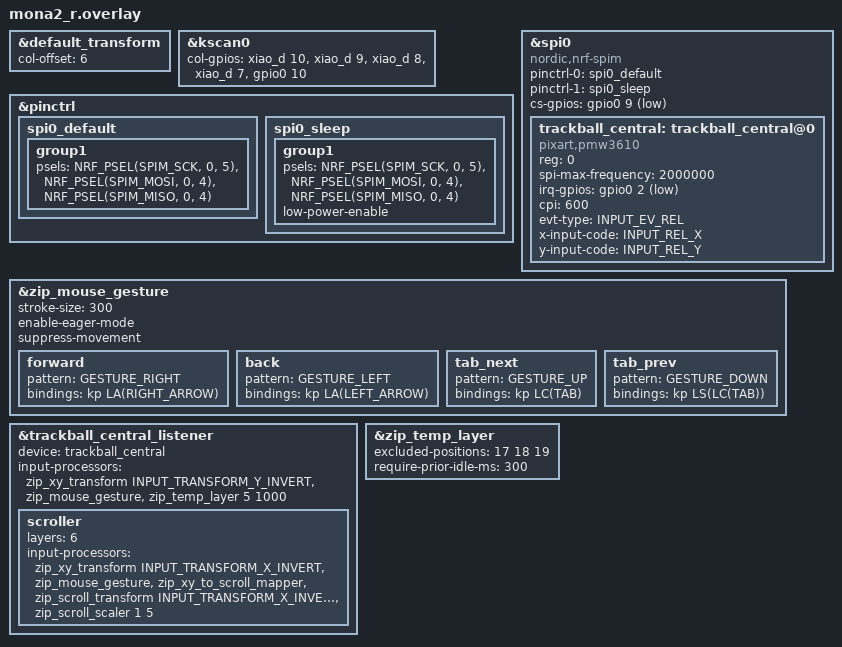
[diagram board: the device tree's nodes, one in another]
#include "mona2.dtsi"
#include <input/processors.dtsi>
#include <zephyr/dt-bindings/input/input-event-codes.h>
#include <dt-bindings/zmk/pointing.h>
#include <dt-bindings/zmk/keys.h>
#include <mouse-gesture.dtsi>


&default_transform {
    col-offset = <6>;
};

&kscan0 {
        col-gpios
            = <&xiao_d 10 GPIO_ACTIVE_HIGH>
            , <&xiao_d 9 GPIO_ACTIVE_HIGH> 
            , <&xiao_d 8 GPIO_ACTIVE_HIGH> 
            , <&xiao_d 7 GPIO_ACTIVE_HIGH> 
            , <&gpio0 10 GPIO_ACTIVE_HIGH>
            ;
};


&pinctrl {
    spi0_default: spi0_default {    //通常時(SPI通信中)のピン構成
        group1 {
            psels = <NRF_PSEL(SPIM_SCK, 0, 5)>, //P0.05を指定(SCLK)
                <NRF_PSEL(SPIM_MOSI, 0, 4)>,    //P0.04を指定(SDIOだからMOSI,MISO両方の役割を担う)
                <NRF_PSEL(SPIM_MISO, 0, 4)>;
        };
    };

    spi0_sleep: spi0_sleep {    //スリープ時のピン構成(省電力)
        group1 {
            psels = <NRF_PSEL(SPIM_SCK, 0, 5)>,
                <NRF_PSEL(SPIM_MOSI, 0, 4)>,
                <NRF_PSEL(SPIM_MISO, 0, 4)>;
            low-power-enable;
        };
    };
};


&spi0 {
    status = "okay";
    compatible = "nordic,nrf-spim"; //マイコンがnRFシリーズ
    pinctrl-0 = <&spi0_default>;
    pinctrl-1 = <&spi0_sleep>;
    pinctrl-names = "default", "sleep";
    cs-gpios = <&gpio0 9 GPIO_ACTIVE_LOW>;  //P0.09を指定(CS)

    trackball_central: trackball_central@0 {
        status = "okay";
        compatible = "pixart,pmw3610";  //トラボセンサ用のドライバとバインド
        reg = <0>;
        spi-max-frequency = <2000000>;
        irq-gpios = <&gpio0 2 (GPIO_ACTIVE_LOW | GPIO_PULL_UP)>; //P0.02を指定(MOTION)
        cpi = <600>;
        //swap-xy;
        //invert-x; //COROPIT版ではコメントアウトを外す
        //invert-y; //COROPIT版ではコメントアウトを外す
        evt-type = <INPUT_EV_REL>;
        x-input-code = <INPUT_REL_X>;
        y-input-code = <INPUT_REL_Y>;
    };
};

/* Mouse gesture: aerogu34と同じ内容(左右移動=進む/戻る、上下=タブ切替)。
 * J+K+Lコンボ(keymap側)が押されている間だけ発動する。 */
&zip_mouse_gesture {
    stroke-size = <300>;
    enable-eager-mode;
    suppress-movement;

    forward {
        pattern = <GESTURE_RIGHT>;
        bindings = <&kp LA(RIGHT_ARROW)>;  /* Alt+Right: forward */
    };

    back {
        pattern = <GESTURE_LEFT>;
        bindings = <&kp LA(LEFT_ARROW)>;   /* Alt+Left: back */
    };

    tab_next {
        pattern = <GESTURE_UP>;
        bindings = <&kp LC(TAB)>;          /* Ctrl+Tab: next tab */
    };

    tab_prev {
        pattern = <GESTURE_DOWN>;
        bindings = <&kp LS(LC(TAB))>;      /* Ctrl+Shift+Tab: previous tab */
    };
};

// Overrides for the input listener node
&trackball_central_listener {
    status = "okay";
    device = <&trackball_central>;

    /* デフォルト(SCROLLレイヤー以外)のチェーン:
     * 元のY軸反転はそのまま維持し、ジェスチャー認識とAML(自動マウス
     * レイヤー)を追加。aerogu34同様、J/K/Lタイプ直後300msはAMLが
     * 発動しないようにしてトラボ誤爆を防止(この機能がv0.3-branchの
     * zip_temp_layerで使えない場合は、下のexcluded-positions/
     * require-prior-idle-msを削除した簡易版に切り替えてください)。 */
    input-processors =
        <&zip_xy_transform INPUT_TRANSFORM_Y_INVERT>,
        <&zip_mouse_gesture>,
        <&zip_temp_layer 5 1000>;

    scroller {
        layers = <6>;
        input-processors = 
            // <&zip_xy_transform INPUT_TRANSFORM_XY_SWAP>,        //X軸とY軸の入れ替え
            <&zip_xy_transform INPUT_TRANSFORM_X_INVERT>,       //X軸反転
            <&zip_mouse_gesture>,
            <&zip_xy_to_scroll_mapper>,                         //スクロールモードに変更
            <&zip_scroll_transform INPUT_TRANSFORM_X_INVERT>,   //スクロールのX軸反転
            <&zip_scroll_scaler 1 5>;                           //スクロール量を1/4倍
    };
};

/* AML(自動マウスレイヤー)。J/K/Lをタイプした直後300msは発動しない
 * (トラボ誤爆防止)。前述の通り、v0.3-branchでこのプロパティが
 * 使えるかは未確認。 */
&zip_temp_layer {
    excluded-positions = <
        17 // J
        18 // K
        19 // L
    >;
    require-prior-idle-ms = <300>;
};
